# ESP32-P4 register map
Vendor: ESPRESSIF SYSTEMS (SHANGHAI) CO., LTD.; Series: ESP32 P-Series; File version: 3
CPU: RV32IMAFC r0p0, little endian, no MPU, FPU, 0 interrupt priority bits
Address unit: 32 bits
Registers are 32-bit, read-write, reset 0x0 unless marked. A register's access mark holds for its fields unless they carry their own. Offsets are from the block's base; [hi:lo] are bit positions; {n}, {i} and the like mark numbered series.

## GPIO_SD — Sigma-Delta Modulation
Base 0x500E0F00
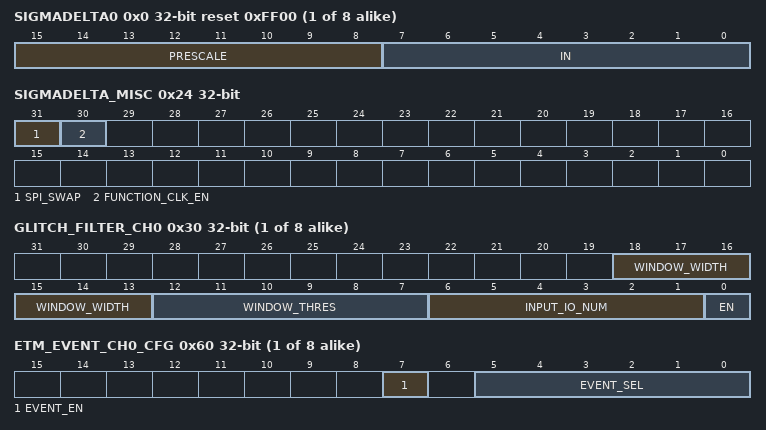
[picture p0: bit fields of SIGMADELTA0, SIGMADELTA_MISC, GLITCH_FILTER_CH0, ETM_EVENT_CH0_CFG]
{0x0+4i} SIGMADELTA{i} (i=0..7) reset 0xFF00 — Duty Cycle Configure Register of SDM{i}
  [15:8] PRESCALE — This field is used to set a divider value to divide APB clock.
  [7:0] IN — This field is used to configure the duty cycle of sigma delta modulation output.
0x20 CLOCK_GATE — Clock Gating Configure Register
  [0] CLK_EN — Clock enable bit of configuration registers for sigma delta modulation.
0x24 SIGMADELTA_MISC — MISC Register
  [31] SPI_SWAP — Reserved.
  [30] FUNCTION_CLK_EN — Clock enable bit of sigma delta modulation.
{0x30+4i} GLITCH_FILTER_CH{i} (i=0..7) — Glitch Filter Configure Register of Channel{i}
  [18:13] WINDOW_WIDTH — Glitch Filter window width.
  [12:7] WINDOW_THRES — Glitch Filter window threshold.
  [6:1] INPUT_IO_NUM — Glitch Filter input io number.
  [0] EN — Glitch Filter channel enable bit.
{0x60+4i} ETM_EVENT_CH{i}_CFG (i=0..7) — Etm Config register of Channel{i}
  [7] EVENT_EN — Etm event send enable bit.
  [5:0] EVENT_SEL — Etm event channel select gpio.
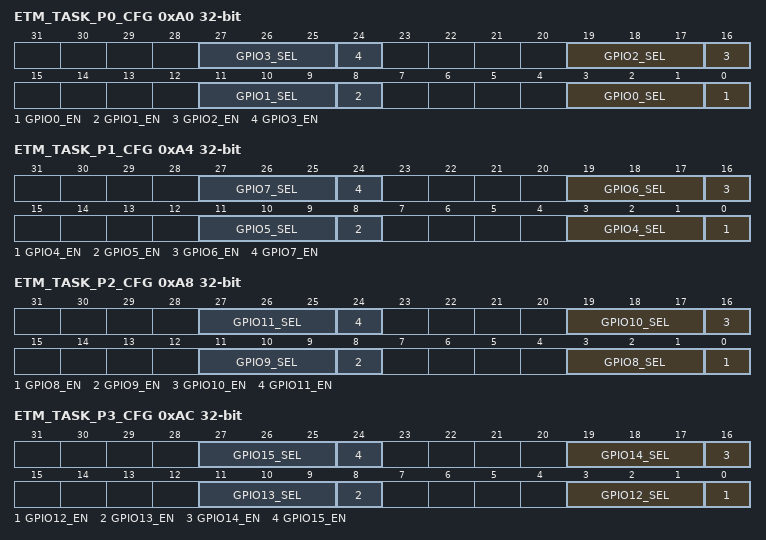
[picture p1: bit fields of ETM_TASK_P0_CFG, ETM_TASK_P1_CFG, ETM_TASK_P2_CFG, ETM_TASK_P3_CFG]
0xA0 ETM_TASK_P0_CFG — Etm Configure Register to decide which GPIO been chosen
  [8n+3:8n+1] GPIO{n}_SEL (n=0..3) — GPIO choose a etm task channel.
  [8n] GPIO{n}_EN (n=0..3) — Enable bit of GPIO response etm task.
0xA4 ETM_TASK_P1_CFG — Etm Configure Register to decide which GPIO been chosen
  [8n-29:8n-31] GPIO{n}_SEL (n=4..7) — GPIO choose a etm task channel.
  [8n-32] GPIO{n}_EN (n=4..7) — Enable bit of GPIO response etm task.
0xA8 ETM_TASK_P2_CFG — Etm Configure Register to decide which GPIO been chosen
  [8n-61:8n-63] GPIO{n}_SEL (n=8..11) — GPIO choose a etm task channel.
  [8n-64] GPIO{n}_EN (n=8..11) — Enable bit of GPIO response etm task.
0xAC ETM_TASK_P3_CFG — Etm Configure Register to decide which GPIO been chosen
  [8n-93:8n-95] GPIO{n}_SEL (n=12..15) — GPIO choose a etm task channel.
  [8n-96] GPIO{n}_EN (n=12..15) — Enable bit of GPIO response etm task.
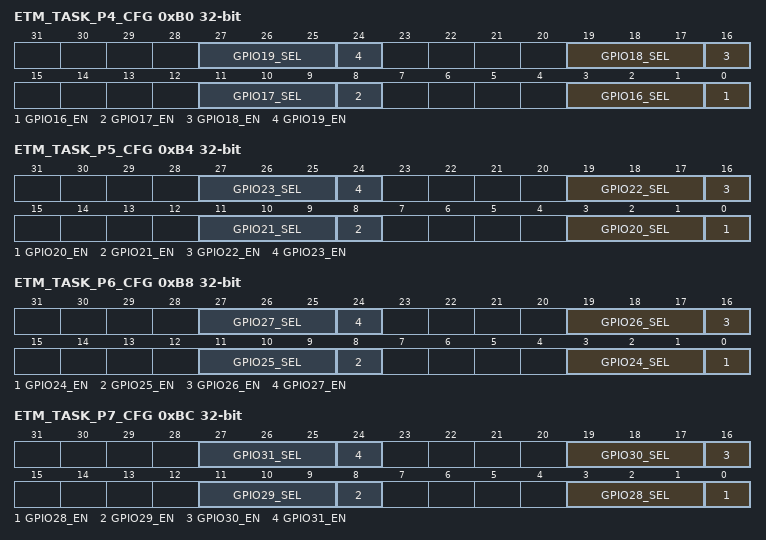
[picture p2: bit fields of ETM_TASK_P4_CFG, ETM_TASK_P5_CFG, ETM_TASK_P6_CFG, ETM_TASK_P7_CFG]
0xB0 ETM_TASK_P4_CFG — Etm Configure Register to decide which GPIO been chosen
  [8n-125:8n-127] GPIO{n}_SEL (n=16..19) — GPIO choose a etm task channel.
  [8n-128] GPIO{n}_EN (n=16..19) — Enable bit of GPIO response etm task.
0xB4 ETM_TASK_P5_CFG — Etm Configure Register to decide which GPIO been chosen
  [8n-157:8n-159] GPIO{n}_SEL (n=20..23) — GPIO choose a etm task channel.
  [8n-160] GPIO{n}_EN (n=20..23) — Enable bit of GPIO response etm task.
0xB8 ETM_TASK_P6_CFG — Etm Configure Register to decide which GPIO been chosen
  [8n-189:8n-191] GPIO{n}_SEL (n=24..27) — GPIO choose a etm task channel.
  [8n-192] GPIO{n}_EN (n=24..27) — Enable bit of GPIO response etm task.
0xBC ETM_TASK_P7_CFG — Etm Configure Register to decide which GPIO been chosen
  [8n-221:8n-223] GPIO{n}_SEL (n=28..31) — GPIO choose a etm task channel.
  [8n-224] GPIO{n}_EN (n=28..31) — Enable bit of GPIO response etm task.
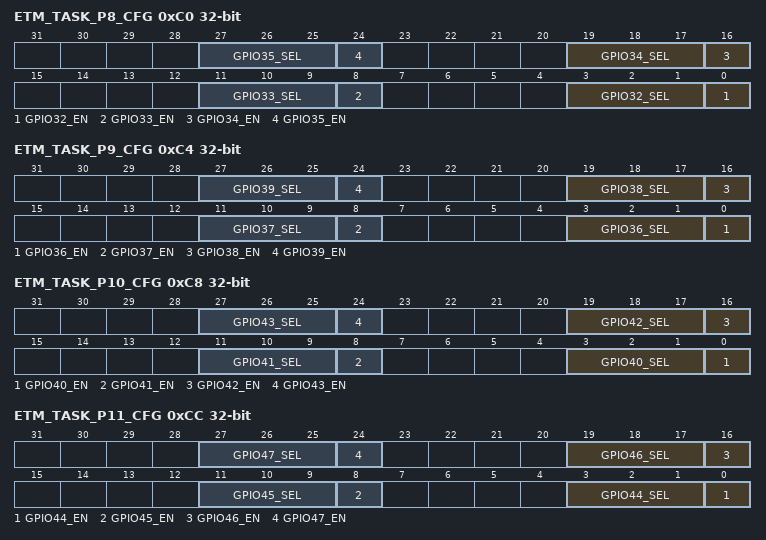
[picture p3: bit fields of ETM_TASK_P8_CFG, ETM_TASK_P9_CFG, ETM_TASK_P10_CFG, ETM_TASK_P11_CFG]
0xC0 ETM_TASK_P8_CFG — Etm Configure Register to decide which GPIO been chosen
  [8n-253:8n-255] GPIO{n}_SEL (n=32..35) — GPIO choose a etm task channel.
  [8n-256] GPIO{n}_EN (n=32..35) — Enable bit of GPIO response etm task.
0xC4 ETM_TASK_P9_CFG — Etm Configure Register to decide which GPIO been chosen
  [8n-285:8n-287] GPIO{n}_SEL (n=36..39) — GPIO choose a etm task channel.
  [8n-288] GPIO{n}_EN (n=36..39) — Enable bit of GPIO response etm task.
0xC8 ETM_TASK_P10_CFG — Etm Configure Register to decide which GPIO been chosen
  [8n-317:8n-319] GPIO{n}_SEL (n=40..43) — GPIO choose a etm task channel.
  [8n-320] GPIO{n}_EN (n=40..43) — Enable bit of GPIO response etm task.
0xCC ETM_TASK_P11_CFG — Etm Configure Register to decide which GPIO been chosen
  [8n-349:8n-351] GPIO{n}_SEL (n=44..47) — GPIO choose a etm task channel.
  [8n-352] GPIO{n}_EN (n=44..47) — Enable bit of GPIO response etm task.
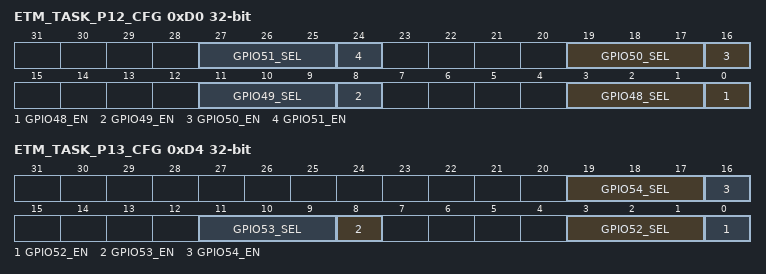
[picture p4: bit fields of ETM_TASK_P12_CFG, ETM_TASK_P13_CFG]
0xD0 ETM_TASK_P12_CFG — Etm Configure Register to decide which GPIO been chosen
  [8n-381:8n-383] GPIO{n}_SEL (n=48..51) — GPIO choose a etm task channel.
  [8n-384] GPIO{n}_EN (n=48..51) — Enable bit of GPIO response etm task.
0xD4 ETM_TASK_P13_CFG — Etm Configure Register to decide which GPIO been chosen
  [8n-413:8n-415] GPIO{n}_SEL (n=52..54) — GPIO choose a etm task channel.
  [8n-416] GPIO{n}_EN (n=52..54) — Enable bit of GPIO response etm task.
0xFC VERSION reset 0x2203050 — Version Control Register
  [27:0] GPIO_SD_DATE — Version control register.
